# ATmega2564RFR2 register map
Vendor: Atmel; File version: 1.0
CPU: other r0p0, little endian, no MPU, no FPU, 4 interrupt priority bits
Registers are 8-bit, read-write, reset 0x0 unless marked. A register's access mark holds for its fields unless they carry their own. Offsets are from the block's base; [hi:lo] are bit positions.

## SYMCNT — MAC Symbol Counter
Base 0x000000D7
0x00 SCRSTRLL — Symbol Counter Received Frame Timestamp Register LL-Byte
0x01 SCRSTRLH — Symbol Counter Received Frame Timestamp Register LH-Byte
0x02 SCRSTRHL — Symbol Counter Received Frame Timestamp Register HL-Byte
0x03 SCRSTRHH — Symbol Counter Received Frame Timestamp Register HH-Byte
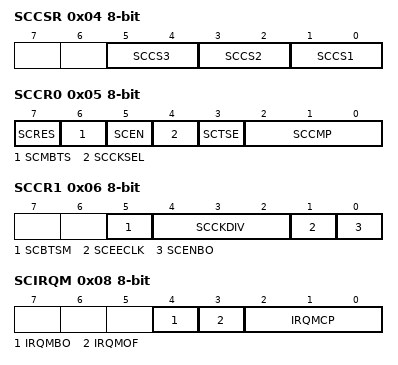
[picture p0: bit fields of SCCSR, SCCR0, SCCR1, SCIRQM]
0x04 SCCSR — Symbol Counter Compare Source Register
  [5:4] SCCS3 — Symbol Counter Compare Source select register for Compare Unit 3
    0=Compare Unit 3 Relative Compare Source = Beacon Timestamp Register; 1=Compare Unit 3 Relative Compare Source = Transmit Frame Timestamp Register; 2=Compare Unit 3 Relative Compare Source = Received Frame Timestamp Register
  [3:2] SCCS2 — Symbol Counter Compare Source select register for Compare Unit 2
    0=Compare Unit 2 Relative Compare Source = Beacon Timestamp Register; 1=Compare Unit 2 Relative Compare Source = Transmit Frame Timestamp Register; 2=Compare Unit 2 Relative Compare Source = Received Frame Timestamp Register
  [1:0] SCCS1 — Symbol Counter Compare Source select register for Compare Units
    0=Compare Unit 1 Relative Compare Source = Beacon Timestamp Register; 1=Compare Unit 1 Relative Compare Source = Transmit Frame Timestamp Register; 2=Compare Unit 1 Relative Compare Source = Received Frame Timestamp Register
0x05 SCCR0 — Symbol Counter Control Register 0
  [7] SCRES — Symbol Counter Synchronization
  [6] SCMBTS — Manual Beacon Timestamp
  [5] SCEN — Symbol Counter enable
  [4] SCCKSEL — Symbol Counter Clock Source select
  [3] SCTSE — Symbol Counter Automatic Timestamping enable
  [2:0] SCCMP — Symbol Counter Compare Unit 3 Mode select
0x06 SCCR1 — Symbol Counter Control Register 1
  [5] SCBTSM — Symbol Counter Beacon Timestamp Mask Register
  [4:2] SCCKDIV — Clock divider for synchronous clock source (16MHz Transceiver Clock)
    0=Transceiver Clock divided by 256, (62.5kHz); 1=Transceiver Clock divided by 128, (125kHz); 2=Transceiver Clock divided by 64, (250kHz); 3=Transceiver Clock divided by 32, (500kHz); 4=Transceiver Clock divided by 16, (1MHz); 5=Transceiver Clock divided by 8, (2MHz); 6=Transceiver Clock divided by 4, (4MHz)
  [1] SCEECLK — Enable External Clock Source on PG2
  [0] SCENBO — Backoff Slot Counter enable
0x07 SCSR — Symbol Counter Status Register
  [0] SCBSY — Symbol Counter busy
0x08 SCIRQM — Symbol Counter Interrupt Mask Register
  [4] IRQMBO — Backoff Slot Counter IRQ enable
  [3] IRQMOF — Symbol Counter Overflow IRQ enable
  [2:0] IRQMCP — Symbol Counter Compare Match 3 IRQ enable
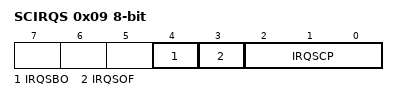
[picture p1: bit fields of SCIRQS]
0x09 SCIRQS — Symbol Counter Interrupt Status Register
  [4] IRQSBO — Backoff Slot Counter IRQ
  [3] IRQSOF — Symbol Counter Overflow IRQ
  [2:0] IRQSCP — Compare Unit 3 Compare Match IRQ
0x0A SCCNTLL — Symbol Counter Register LL-Byte
0x0B SCCNTLH — Symbol Counter Register LH-Byte
0x0C SCCNTHL — Symbol Counter Register HL-Byte
0x0D SCCNTHH — Symbol Counter Register HH-Byte
0x0E SCBTSRLL — Symbol Counter Beacon Timestamp Register LL-Byte
0x0F SCBTSRLH — Symbol Counter Beacon Timestamp Register LH-Byte
0x10 SCBTSRHL — Symbol Counter Beacon Timestamp Register HL-Byte
0x11 SCBTSRHH — Symbol Counter Beacon Timestamp Register HH-Byte
0x12 SCTSRLL — Symbol Counter Frame Timestamp Register LL-Byte
0x13 SCTSRLH — Symbol Counter Frame Timestamp Register LH-Byte
0x14 SCTSRHL — Symbol Counter Frame Timestamp Register HL-Byte
0x15 SCTSRHH — Symbol Counter Frame Timestamp Register HH-Byte
0x16 SCOCR3LL — Symbol Counter Output Compare Register 3 LL-Byte
0x17 SCOCR3LH — Symbol Counter Output Compare Register 3 LH-Byte
0x18 SCOCR3HL — Symbol Counter Output Compare Register 3 HL-Byte
0x19 SCOCR3HH — Symbol Counter Output Compare Register 3 HH-Byte
0x1A SCOCR2LL — Symbol Counter Output Compare Register 2 LL-Byte
0x1B SCOCR2LH — Symbol Counter Output Compare Register 2 LH-Byte
0x1C SCOCR2HL — Symbol Counter Output Compare Register 2 HL-Byte
0x1D SCOCR2HH — Symbol Counter Output Compare Register 2 HH-Byte
0x1E SCOCR1LL — Symbol Counter Output Compare Register 1 LL-Byte
0x1F SCOCR1LH — Symbol Counter Output Compare Register 1 LH-Byte
0x20 SCOCR1HL — Symbol Counter Output Compare Register 1 HL-Byte
0x21 SCOCR1HH — Symbol Counter Output Compare Register 1 HH-Byte
0x22 SCTSTRLL — Symbol Counter Transmit Frame Timestamp Register LL-Byte
0x23 SCTSTRLH — Symbol Counter Transmit Frame Timestamp Register LH-Byte
0x24 SCTSTRHL — Symbol Counter Transmit Frame Timestamp Register HL-Byte
0x25 SCTSTRHH — Symbol Counter Transmit Frame Timestamp Register HH-Byte
